# UPD70F3508 register map
Vendor: Renesas; Series: V850E2/Px4; File version: 1.0
CPU: other r0p0, little endian, no MPU, FPU, 4 interrupt priority bits
Registers are 8-bit, read-write, reset 0x0 unless marked. A register's access mark holds for its fields unless they carry their own. Offsets are from the block's base; [hi:lo] are bit positions; {n}, {i} and the like mark numbered series.

## INTC — Interrupt Controller
Base 0xFFFF6000
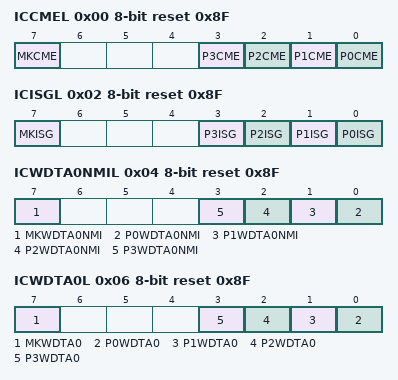
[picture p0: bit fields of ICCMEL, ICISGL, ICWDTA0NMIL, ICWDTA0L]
0x00 ICCMEL reset 0x8F — EI Level Interrupt Control Reg (low byte) ICCME
  [7] MKCME — Interrupt mask bit
  [n] P{n}CME (n=0..3) — Priority bit {n}
0x01 ICCMEH — EI Level Interrupt Control Reg (high byte) ICCME
  [4] RFCME — Interrupt request flag
0x02 ICISGL reset 0x8F — EI Level Interrupt Control Reg (low byte) ICISG
  [7] MKISG — Interrupt mask bit
  [n] P{n}ISG (n=0..3) — Priority bit {n}
0x03 ICISGH — EI Level Interrupt Control Reg (high byte) ICISG
  [4] RFISG — Interrupt request flag
0x04 ICWDTA0NMIL reset 0x8F — EI Level Interrupt Control Reg (low byte) ICWDTA0NMI
  [7] MKWDTA0NMI — Interrupt mask bit
  [n] P{n}WDTA0NMI (n=0..3) — Priority bit {n}
0x05 ICWDTA0NMIH — EI Level Interrupt Control Reg (high byte) ICWDTA0NMI
  [4] RFWDTA0NMI — Interrupt request flag
0x06 ICWDTA0L reset 0x8F — EI Level Interrupt Control Reg (low byte) ICWDTA0
  [7] MKWDTA0 — Interrupt mask bit
  [n] P{n}WDTA0 (n=0..3) — Priority bit {n}
0x07 ICWDTA0H — EI Level Interrupt Control Reg (high byte) ICWDTA0
  [4] RFWDTA0 — Interrupt request flag
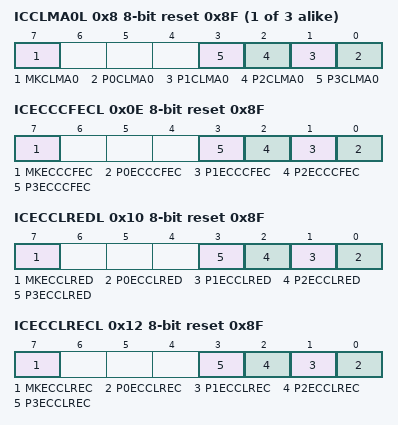
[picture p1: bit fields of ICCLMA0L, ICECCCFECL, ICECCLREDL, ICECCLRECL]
{0x8+2i} ICCLMA{i}L reset 0x8F (i=0..2) — EI Level Interrupt Control Reg (low byte) ICCLMA{i}
  [7] MKCLMA{i} — Interrupt mask bit
  [n] P{n}CLMA{i} (n=0..3) — Priority bit {n}
{0x9+2i} ICCLMA{i}H (i=0..2) — EI Level Interrupt Control Reg (high byte) ICCLMA{i}
  [4] RFCLMA{i} — Interrupt request flag
0x0E ICECCCFECL reset 0x8F — EI Level Interrupt Control Reg (low byte) ICECCCFEC
  [7] MKECCCFEC — Interrupt mask bit
  [n] P{n}ECCCFEC (n=0..3) — Priority bit {n}
0x0F ICECCCFECH — EI Level Interrupt Control Reg (high byte) ICECCCFEC
  [4] RFECCCFEC — Interrupt request flag
0x10 ICECCLREDL reset 0x8F — EI Level Interrupt Control Reg (low byte) ICECCLRED
  [7] MKECCLRED — Interrupt mask bit
  [n] P{n}ECCLRED (n=0..3) — Priority bit {n}
0x11 ICECCLREDH — EI Level Interrupt Control Reg (high byte) ICECCLRED
  [4] RFECCLRED — Interrupt request flag
0x12 ICECCLRECL reset 0x8F — EI Level Interrupt Control Reg (low byte) ICECCLREC
  [7] MKECCLREC — Interrupt mask bit
  [n] P{n}ECCLREC (n=0..3) — Priority bit {n}
0x13 ICECCLRECH — EI Level Interrupt Control Reg (high byte) ICECCLREC
  [4] RFECCLREC — Interrupt request flag
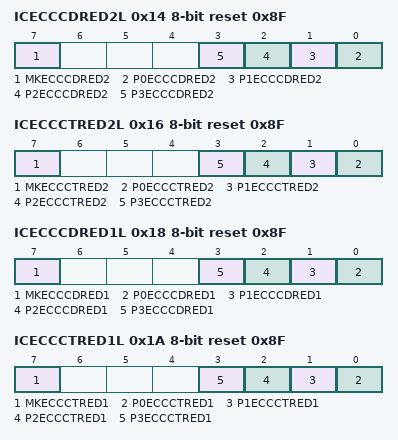
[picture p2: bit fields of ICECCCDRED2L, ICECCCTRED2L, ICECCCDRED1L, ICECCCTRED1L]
0x14 ICECCCDRED2L reset 0x8F — EI Level Interrupt Control Reg (low byte) ICECCCDRED2
  [7] MKECCCDRED2 — Interrupt mask bit
  [n] P{n}ECCCDRED2 (n=0..3) — Priority bit {n}
0x15 ICECCCDRED2H — EI Level Interrupt Control Reg (high byte) ICECCCDRED2
  [4] RFECCCDRED2 — Interrupt request flag
0x16 ICECCCTRED2L reset 0x8F — EI Level Interrupt Control Reg (low byte) ICECCCTRED2
  [7] MKECCCTRED2 — Interrupt mask bit
  [n] P{n}ECCCTRED2 (n=0..3) — Priority bit {n}
0x17 ICECCCTRED2H — EI Level Interrupt Control Reg (high byte) ICECCCTRED2
  [4] RFECCCTRED2 — Interrupt request flag
0x18 ICECCCDRED1L reset 0x8F — EI Level Interrupt Control Reg (low byte) ICECCCDRED1
  [7] MKECCCDRED1 — Interrupt mask bit
  [n] P{n}ECCCDRED1 (n=0..3) — Priority bit {n}
0x19 ICECCCDRED1H — EI Level Interrupt Control Reg (high byte) ICECCCDRED1
  [4] RFECCCDRED1 — Interrupt request flag
0x1A ICECCCTRED1L reset 0x8F — EI Level Interrupt Control Reg (low byte) ICECCCTRED1
  [7] MKECCCTRED1 — Interrupt mask bit
  [n] P{n}ECCCTRED1 (n=0..3) — Priority bit {n}
0x1B ICECCCTRED1H — EI Level Interrupt Control Reg (high byte) ICECCCTRED1
  [4] RFECCCTRED1 — Interrupt request flag
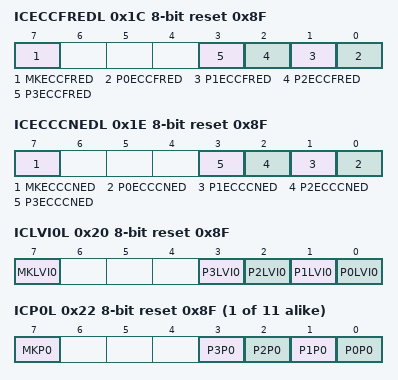
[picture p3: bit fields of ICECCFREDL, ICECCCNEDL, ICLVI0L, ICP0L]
0x1C ICECCFREDL reset 0x8F — EI Level Interrupt Control Reg (low byte) ICECCFRED
  [7] MKECCFRED — Interrupt mask bit
  [n] P{n}ECCFRED (n=0..3) — Priority bit {n}
0x1D ICECCFREDH — EI Level Interrupt Control Reg (high byte) ICECCFRED
  [4] RFECCFRED — Interrupt request flag
0x1E ICECCCNEDL reset 0x8F — EI Level Interrupt Control Reg (low byte) ICECCCNED
  [7] MKECCCNED — Interrupt mask bit
  [n] P{n}ECCCNED (n=0..3) — Priority bit {n}
0x1F ICECCCNEDH — EI Level Interrupt Control Reg (high byte) ICECCCNED
  [4] RFECCCNED — Interrupt request flag
0x20 ICLVI0L reset 0x8F — EI Level Interrupt Control Reg (low byte) ICLVI0
  [7] MKLVI0 — Interrupt mask bit
  [n] P{n}LVI0 (n=0..3) — Priority bit {n}
0x21 ICLVI0H — EI Level Interrupt Control Reg (high byte) ICLVI0
  [4] RFLVI0 — Interrupt request flag
{0x22+2i} ICP{i}L reset 0x8F (i=0..10) — EI Level Interrupt Control Reg (low byte) ICP{i}
  [7] MKP{i} — Interrupt mask bit
  [n] P{n}P{i} (n=0..3) — Priority bit {n}
{0x23+2i} ICP{i}H (i=0..10) — EI Level Interrupt Control Reg (high byte) ICP{i}
  [4] RFP{i} — Interrupt request flag
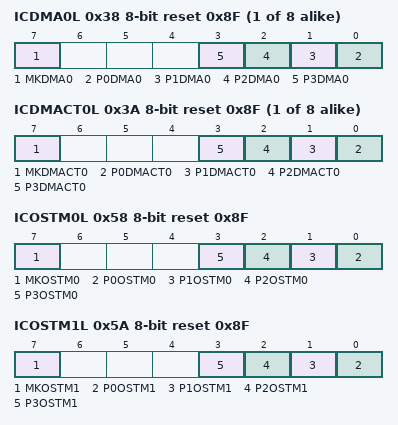
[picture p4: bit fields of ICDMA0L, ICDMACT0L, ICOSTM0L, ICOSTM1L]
{0x38+4i} ICDMA{i}L reset 0x8F (i=0..7) — EI Level Interrupt Control Reg (low byte) ICDMA{i}
  [7] MKDMA{i} — Interrupt mask bit
  [n] P{n}DMA{i} (n=0..3) — Priority bit {n}
{0x39+4i} ICDMA{i}H (i=0..7) — EI Level Interrupt Control Reg (high byte) ICDMA{i}
  [4] RFDMA{i} — Interrupt request flag
{0x3A+4i} ICDMACT{i}L reset 0x8F (i=0..7) — EI Level Interrupt Control Reg (low byte) ICDMACT{i}
  [7] MKDMACT{i} — Interrupt mask bit
  [n] P{n}DMACT{i} (n=0..3) — Priority bit {n}
{0x3B+4i} ICDMACT{i}H (i=0..7) — EI Level Interrupt Control Reg (high byte) ICDMACT{i}
  [4] RFDMACT{i} — Interrupt request flag
0x58 ICOSTM0L reset 0x8F — EI Level Interrupt Control Reg (low byte) ICOSTM0
  [7] MKOSTM0 — Interrupt mask bit
  [n] P{n}OSTM0 (n=0..3) — Priority bit {n}
0x59 ICOSTM0H — EI Level Interrupt Control Reg (high byte) ICOSTM0
  [4] RFOSTM0 — Interrupt request flag
0x5A ICOSTM1L reset 0x8F — EI Level Interrupt Control Reg (low byte) ICOSTM1
  [7] MKOSTM1 — Interrupt mask bit
  [n] P{n}OSTM1 (n=0..3) — Priority bit {n}
0x5B ICOSTM1H — EI Level Interrupt Control Reg (high byte) ICOSTM1
  [4] RFOSTM1 — Interrupt request flag
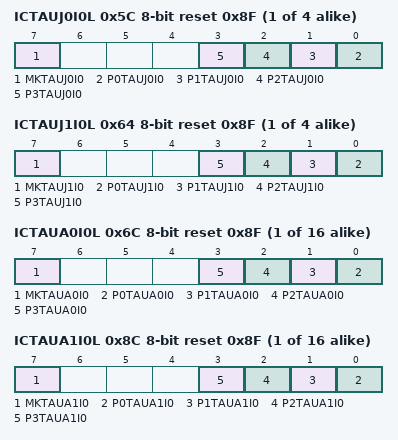
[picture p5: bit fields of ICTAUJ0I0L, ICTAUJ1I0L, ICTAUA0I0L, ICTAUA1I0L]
{0x5C+2i} ICTAUJ0I{i}L reset 0x8F (i=0..3) — EI Level Interrupt Control Reg (low byte) ICTAUJ0I{i}
  [7] MKTAUJ0I{i} — Interrupt mask bit
  [n] P{n}TAUJ0I{i} (n=0..3) — Priority bit {n}
{0x5D+2i} ICTAUJ0I{i}H (i=0..3) — EI Level Interrupt Control Reg (high byte) ICTAUJ0I{i}
  [4] RFTAUJ0I{i} — Interrupt request flag
{0x64+2i} ICTAUJ1I{i}L reset 0x8F (i=0..3) — EI Level Interrupt Control Reg (low byte) ICTAUJ1I{i}
  [7] MKTAUJ1I{i} — Interrupt mask bit
  [n] P{n}TAUJ1I{i} (n=0..3) — Priority bit {n}
{0x65+2i} ICTAUJ1I{i}H (i=0..3) — EI Level Interrupt Control Reg (high byte) ICTAUJ1I{i}
  [4] RFTAUJ1I{i} — Interrupt request flag
{0x6C+2i} ICTAUA0I{i}L reset 0x8F (i=0..15) — EI Level Interrupt Control Reg (low byte) ICTAUA0I{i}
  [7] MKTAUA0I{i} — Interrupt mask bit
  [n] P{n}TAUA0I{i} (n=0..3) — Priority bit {n}
{0x6D+2i} ICTAUA0I{i}H (i=0..15) — EI Level Interrupt Control Reg (high byte) ICTAUA0I{i}
  [4] RFTAUA0I{i} — Interrupt request flag
{0x8C+2i} ICTAUA1I{i}L reset 0x8F (i=0..15) — EI Level Interrupt Control Reg (low byte) ICTAUA1I{i}
  [7] MKTAUA1I{i} — Interrupt mask bit
  [n] P{n}TAUA1I{i} (n=0..3) — Priority bit {n}
{0x8D+2i} ICTAUA1I{i}H (i=0..15) — EI Level Interrupt Control Reg (high byte) ICTAUA1I{i}
  [4] RFTAUA1I{i} — Interrupt request flag
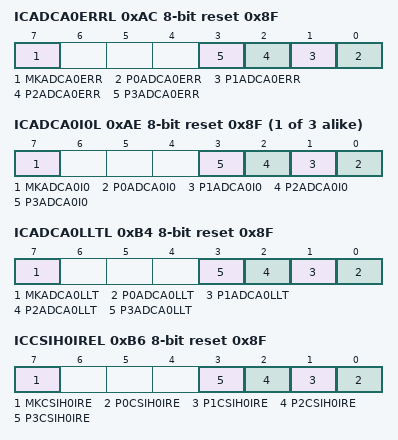
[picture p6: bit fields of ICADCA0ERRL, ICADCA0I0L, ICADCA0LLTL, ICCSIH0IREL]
0xAC ICADCA0ERRL reset 0x8F — EI Level Interrupt Control Reg (low byte) ICADCA0ERR
  [7] MKADCA0ERR — Interrupt mask bit
  [n] P{n}ADCA0ERR (n=0..3) — Priority bit {n}
0xAD ICADCA0ERRH — EI Level Interrupt Control Reg (high byte) ICADCA0ERR
  [4] RFADCA0ERR — Interrupt request flag
{0xAE+2i} ICADCA0I{i}L reset 0x8F (i=0..2) — EI Level Interrupt Control Reg (low byte) ICADCA0I{i}
  [7] MKADCA0I{i} — Interrupt mask bit
  [n] P{n}ADCA0I{i} (n=0..3) — Priority bit {n}
{0xAF+2i} ICADCA0I{i}H (i=0..2) — EI Level Interrupt Control Reg (high byte) ICADCA0I{i}
  [4] RFADCA0I{i} — Interrupt request flag
0xB4 ICADCA0LLTL reset 0x8F — EI Level Interrupt Control Reg (low byte) ICADCA0LLT
  [7] MKADCA0LLT — Interrupt mask bit
  [n] P{n}ADCA0LLT (n=0..3) — Priority bit {n}
0xB5 ICADCA0LLTH — EI Level Interrupt Control Reg (high byte) ICADCA0LLT
  [4] RFADCA0LLT — Interrupt request flag
0xB6 ICCSIH0IREL reset 0x8F — EI Level Interrupt Control Reg (low byte) ICCSIH0IRE
  [7] MKCSIH0IRE — Interrupt mask bit
  [n] P{n}CSIH0IRE (n=0..3) — Priority bit {n}
0xB7 ICCSIH0IREH — EI Level Interrupt Control Reg (high byte) ICCSIH0IRE
  [4] RFCSIH0IRE — Interrupt request flag
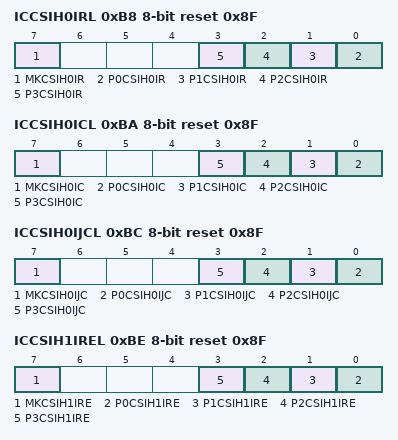
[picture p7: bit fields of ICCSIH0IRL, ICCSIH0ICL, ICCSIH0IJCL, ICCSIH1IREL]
0xB8 ICCSIH0IRL reset 0x8F — EI Level Interrupt Control Reg (low byte) ICCSIH0IR
  [7] MKCSIH0IR — Interrupt mask bit
  [n] P{n}CSIH0IR (n=0..3) — Priority bit {n}
0xB9 ICCSIH0IRH — EI Level Interrupt Control Reg (high byte) ICCSIH0IR
  [4] RFCSIH0IR — Interrupt request flag
0xBA ICCSIH0ICL reset 0x8F — EI Level Interrupt Control Reg (low byte) ICCSIH0IC
  [7] MKCSIH0IC — Interrupt mask bit
  [n] P{n}CSIH0IC (n=0..3) — Priority bit {n}
0xBB ICCSIH0ICH — EI Level Interrupt Control Reg (high byte) ICCSIH0IC
  [4] RFCSIH0IC — Interrupt request flag
0xBC ICCSIH0IJCL reset 0x8F — EI Level Interrupt Control Reg (low byte) ICCSIH0IJC
  [7] MKCSIH0IJC — Interrupt mask bit
  [n] P{n}CSIH0IJC (n=0..3) — Priority bit {n}
0xBD ICCSIH0IJCH — EI Level Interrupt Control Reg (high byte) ICCSIH0IJC
  [4] RFCSIH0IJC — Interrupt request flag
0xBE ICCSIH1IREL reset 0x8F — EI Level Interrupt Control Reg (low byte) ICCSIH1IRE
  [7] MKCSIH1IRE — Interrupt mask bit
  [n] P{n}CSIH1IRE (n=0..3) — Priority bit {n}
0xBF ICCSIH1IREH — EI Level Interrupt Control Reg (high byte) ICCSIH1IRE
  [4] RFCSIH1IRE — Interrupt request flag
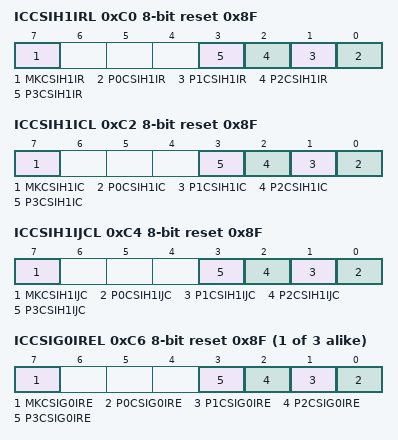
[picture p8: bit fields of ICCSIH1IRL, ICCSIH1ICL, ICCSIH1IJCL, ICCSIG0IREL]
0xC0 ICCSIH1IRL reset 0x8F — EI Level Interrupt Control Reg (low byte) ICCSIH1IR
  [7] MKCSIH1IR — Interrupt mask bit
  [n] P{n}CSIH1IR (n=0..3) — Priority bit {n}
0xC1 ICCSIH1IRH — EI Level Interrupt Control Reg (high byte) ICCSIH1IR
  [4] RFCSIH1IR — Interrupt request flag
0xC2 ICCSIH1ICL reset 0x8F — EI Level Interrupt Control Reg (low byte) ICCSIH1IC
  [7] MKCSIH1IC — Interrupt mask bit
  [n] P{n}CSIH1IC (n=0..3) — Priority bit {n}
0xC3 ICCSIH1ICH — EI Level Interrupt Control Reg (high byte) ICCSIH1IC
  [4] RFCSIH1IC — Interrupt request flag
0xC4 ICCSIH1IJCL reset 0x8F — EI Level Interrupt Control Reg (low byte) ICCSIH1IJC
  [7] MKCSIH1IJC — Interrupt mask bit
  [n] P{n}CSIH1IJC (n=0..3) — Priority bit {n}
0xC5 ICCSIH1IJCH — EI Level Interrupt Control Reg (high byte) ICCSIH1IJC
  [4] RFCSIH1IJC — Interrupt request flag
{0xC6+6i} ICCSIG{i}IREL reset 0x8F (i=0..2) — EI Level Interrupt Control Reg (low byte) ICCSIG{i}IRE
  [7] MKCSIG{i}IRE — Interrupt mask bit
  [n] P{n}CSIG{i}IRE (n=0..3) — Priority bit {n}
{0xC7+6i} ICCSIG{i}IREH (i=0..2) — EI Level Interrupt Control Reg (high byte) ICCSIG{i}IRE
  [4] RFCSIG{i}IRE — Interrupt request flag
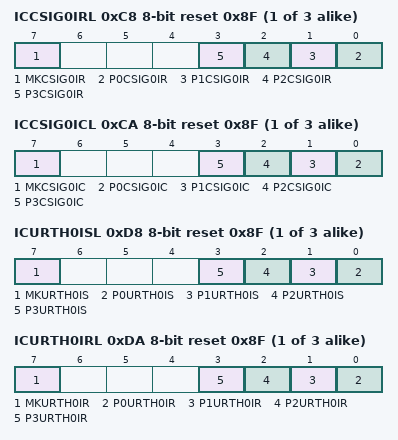
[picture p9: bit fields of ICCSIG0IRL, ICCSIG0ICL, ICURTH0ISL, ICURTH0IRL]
{0xC8+6i} ICCSIG{i}IRL reset 0x8F (i=0..2) — EI Level Interrupt Control Reg (low byte) ICCSIG{i}IR
  [7] MKCSIG{i}IR — Interrupt mask bit
  [n] P{n}CSIG{i}IR (n=0..3) — Priority bit {n}
{0xC9+6i} ICCSIG{i}IRH (i=0..2) — EI Level Interrupt Control Reg (high byte) ICCSIG{i}IR
  [4] RFCSIG{i}IR — Interrupt request flag
{0xCA+6i} ICCSIG{i}ICL reset 0x8F (i=0..2) — EI Level Interrupt Control Reg (low byte) ICCSIG{i}IC
  [7] MKCSIG{i}IC — Interrupt mask bit
  [n] P{n}CSIG{i}IC (n=0..3) — Priority bit {n}
{0xCB+6i} ICCSIG{i}ICH (i=0..2) — EI Level Interrupt Control Reg (high byte) ICCSIG{i}IC
  [4] RFCSIG{i}IC — Interrupt request flag
{0xD8+6i} ICURTH{i}ISL reset 0x8F (i=0..2) — EI Level Interrupt Control Reg (low byte) ICURTH{i}IS
  [7] MKURTH{i}IS — Interrupt mask bit
  [n] P{n}URTH{i}IS (n=0..3) — Priority bit {n}
{0xD9+6i} ICURTH{i}ISH (i=0..2) — EI Level Interrupt Control Reg (high byte) ICURTH{i}IS
  [4] RFURTH{i}IS — Interrupt request flag
{0xDA+6i} ICURTH{i}IRL reset 0x8F (i=0..2) — EI Level Interrupt Control Reg (low byte) ICURTH{i}IR
  [7] MKURTH{i}IR — Interrupt mask bit
  [n] P{n}URTH{i}IR (n=0..3) — Priority bit {n}
{0xDB+6i} ICURTH{i}IRH (i=0..2) — EI Level Interrupt Control Reg (high byte) ICURTH{i}IR
  [4] RFURTH{i}IR — Interrupt request flag
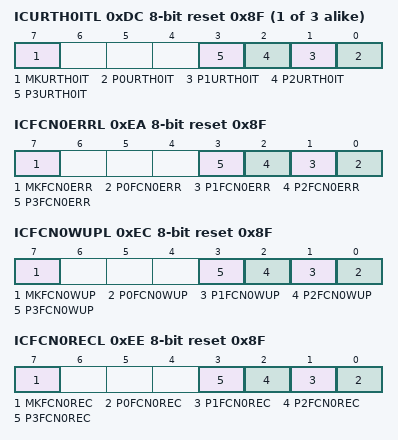
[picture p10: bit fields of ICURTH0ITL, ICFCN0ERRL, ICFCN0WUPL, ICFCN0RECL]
{0xDC+6i} ICURTH{i}ITL reset 0x8F (i=0..2) — EI Level Interrupt Control Reg (low byte) ICURTH{i}IT
  [7] MKURTH{i}IT — Interrupt mask bit
  [n] P{n}URTH{i}IT (n=0..3) — Priority bit {n}
{0xDD+6i} ICURTH{i}ITH (i=0..2) — EI Level Interrupt Control Reg (high byte) ICURTH{i}IT
  [4] RFURTH{i}IT — Interrupt request flag
0xEA ICFCN0ERRL reset 0x8F — EI Level Interrupt Control Reg (low byte) ICFCN0ERR
  [7] MKFCN0ERR — Interrupt mask bit
  [n] P{n}FCN0ERR (n=0..3) — Priority bit {n}
0xEB ICFCN0ERRH — EI Level Interrupt Control Reg (high byte) ICFCN0ERR
  [4] RFFCN0ERR — Interrupt request flag
0xEC ICFCN0WUPL reset 0x8F — EI Level Interrupt Control Reg (low byte) ICFCN0WUP
  [7] MKFCN0WUP — Interrupt mask bit
  [n] P{n}FCN0WUP (n=0..3) — Priority bit {n}
0xED ICFCN0WUPH — EI Level Interrupt Control Reg (high byte) ICFCN0WUP
  [4] RFFCN0WUP — Interrupt request flag
0xEE ICFCN0RECL reset 0x8F — EI Level Interrupt Control Reg (low byte) ICFCN0REC
  [7] MKFCN0REC — Interrupt mask bit
  [n] P{n}FCN0REC (n=0..3) — Priority bit {n}
0xEF ICFCN0RECH — EI Level Interrupt Control Reg (high byte) ICFCN0REC
  [4] RFFCN0REC — Interrupt request flag
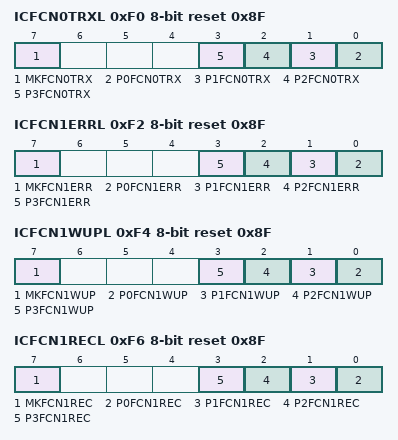
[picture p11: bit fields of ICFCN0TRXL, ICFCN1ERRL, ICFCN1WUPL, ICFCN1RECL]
0xF0 ICFCN0TRXL reset 0x8F — EI Level Interrupt Control Reg (low byte) ICFCN0TRX
  [7] MKFCN0TRX — Interrupt mask bit
  [n] P{n}FCN0TRX (n=0..3) — Priority bit {n}
0xF1 ICFCN0TRXH — EI Level Interrupt Control Reg (high byte) ICFCN0TRX
  [4] RFFCN0TRX — Interrupt request flag
0xF2 ICFCN1ERRL reset 0x8F — EI Level Interrupt Control Reg (low byte) ICFCN1ERR
  [7] MKFCN1ERR — Interrupt mask bit
  [n] P{n}FCN1ERR (n=0..3) — Priority bit {n}
0xF3 ICFCN1ERRH — EI Level Interrupt Control Reg (high byte) ICFCN1ERR
  [4] RFFCN1ERR — Interrupt request flag
0xF4 ICFCN1WUPL reset 0x8F — EI Level Interrupt Control Reg (low byte) ICFCN1WUP
  [7] MKFCN1WUP — Interrupt mask bit
  [n] P{n}FCN1WUP (n=0..3) — Priority bit {n}
0xF5 ICFCN1WUPH — EI Level Interrupt Control Reg (high byte) ICFCN1WUP
  [4] RFFCN1WUP — Interrupt request flag
0xF6 ICFCN1RECL reset 0x8F — EI Level Interrupt Control Reg (low byte) ICFCN1REC
  [7] MKFCN1REC — Interrupt mask bit
  [n] P{n}FCN1REC (n=0..3) — Priority bit {n}
0xF7 ICFCN1RECH — EI Level Interrupt Control Reg (high byte) ICFCN1REC
  [4] RFFCN1REC — Interrupt request flag
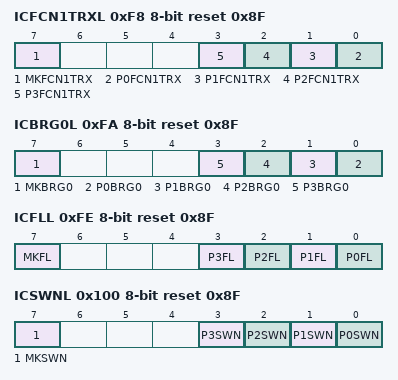
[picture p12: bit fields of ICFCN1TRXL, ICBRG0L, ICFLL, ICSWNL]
0xF8 ICFCN1TRXL reset 0x8F — EI Level Interrupt Control Reg (low byte) ICFCN1TRX
  [7] MKFCN1TRX — Interrupt mask bit
  [n] P{n}FCN1TRX (n=0..3) — Priority bit {n}
0xF9 ICFCN1TRXH — EI Level Interrupt Control Reg (high byte) ICFCN1TRX
  [4] RFFCN1TRX — Interrupt request flag
0xFA ICBRG0L reset 0x8F — EI Level Interrupt Control Reg (low byte) ICBRG0
  [7] MKBRG0 — Interrupt mask bit
  [n] P{n}BRG0 (n=0..3) — Priority bit {n}
0xFB ICBRG0H — EI Level Interrupt Control Reg (high byte) ICBRG0
  [4] RFBRG0 — Interrupt request flag
0xFE ICFLL reset 0x8F — EI Level Interrupt Control Reg (low byte) ICFL
  [7] MKFL — Interrupt mask bit
  [n] P{n}FL (n=0..3) — Priority bit {n}
0xFF ICFLH — EI Level Interrupt Control Reg (high byte) ICFL
  [4] RFFL — Interrupt request flag
0x100 ICSWNL reset 0x8F — EI Level Interrupt Control Reg (low byte) ICSWN
  [7] MKSWN — Interrupt mask bit
  [n] P{n}SWN (n=0..3) — Priority bit {n}
0x101 ICSWNH — EI Level Interrupt Control Reg (high byte) ICSWN
  [4] RFSWN — Interrupt request flag
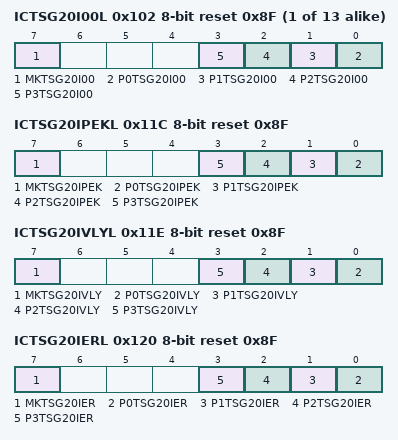
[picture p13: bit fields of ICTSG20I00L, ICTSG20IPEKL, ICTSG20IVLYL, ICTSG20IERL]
{0x102+2i} ICTSG20I{i:02}L reset 0x8F (i=0..12) — EI Level Interrupt Control Reg (low byte) ICTSG20I{i:02}
  [7] MKTSG20I{i:02} — Interrupt mask bit
  [n] P{n}TSG20I{i:02} (n=0..3) — Priority bit {n}
{0x103+2i} ICTSG20I{i:02}H (i=0..12) — EI Level Interrupt Control Reg (high byte) ICTSG20I{i:02}
  [4] RFTSG20I{i:02} — Interrupt request flag
0x11C ICTSG20IPEKL reset 0x8F — EI Level Interrupt Control Reg (low byte) ICTSG20IPEK
  [7] MKTSG20IPEK — Interrupt mask bit
  [n] P{n}TSG20IPEK (n=0..3) — Priority bit {n}
0x11D ICTSG20IPEKH — EI Level Interrupt Control Reg (high byte) ICTSG20IPEK
  [4] RFTSG20IPEK — Interrupt request flag
0x11E ICTSG20IVLYL reset 0x8F — EI Level Interrupt Control Reg (low byte) ICTSG20IVLY
  [7] MKTSG20IVLY — Interrupt mask bit
  [n] P{n}TSG20IVLY (n=0..3) — Priority bit {n}
0x11F ICTSG20IVLYH — EI Level Interrupt Control Reg (high byte) ICTSG20IVLY
  [4] RFTSG20IVLY — Interrupt request flag
0x120 ICTSG20IERL reset 0x8F — EI Level Interrupt Control Reg (low byte) ICTSG20IER
  [7] MKTSG20IER — Interrupt mask bit
  [n] P{n}TSG20IER (n=0..3) — Priority bit {n}
0x121 ICTSG20IERH — EI Level Interrupt Control Reg (high byte) ICTSG20IER
  [4] RFTSG20IER — Interrupt request flag
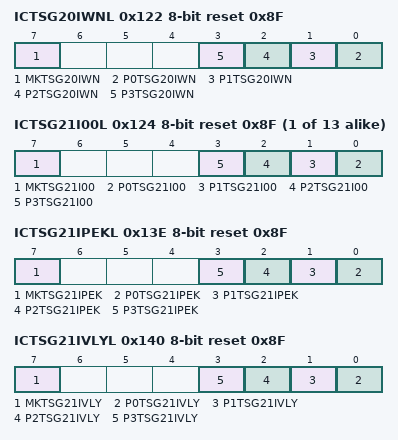
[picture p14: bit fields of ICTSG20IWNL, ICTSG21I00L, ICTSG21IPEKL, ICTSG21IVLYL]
0x122 ICTSG20IWNL reset 0x8F — EI Level Interrupt Control Reg (low byte) ICTSG20IWN
  [7] MKTSG20IWN — Interrupt mask bit
  [n] P{n}TSG20IWN (n=0..3) — Priority bit {n}
0x123 ICTSG20IWNH — EI Level Interrupt Control Reg (high byte) ICTSG20IWN
  [4] RFTSG20IWN — Interrupt request flag
{0x124+2i} ICTSG21I{i:02}L reset 0x8F (i=0..12) — EI Level Interrupt Control Reg (low byte) ICTSG21I{i:02}
  [7] MKTSG21I{i:02} — Interrupt mask bit
  [n] P{n}TSG21I{i:02} (n=0..3) — Priority bit {n}
{0x125+2i} ICTSG21I{i:02}H (i=0..12) — EI Level Interrupt Control Reg (high byte) ICTSG21I{i:02}
  [4] RFTSG21I{i:02} — Interrupt request flag
0x13E ICTSG21IPEKL reset 0x8F — EI Level Interrupt Control Reg (low byte) ICTSG21IPEK
  [7] MKTSG21IPEK — Interrupt mask bit
  [n] P{n}TSG21IPEK (n=0..3) — Priority bit {n}
0x13F ICTSG21IPEKH — EI Level Interrupt Control Reg (high byte) ICTSG21IPEK
  [4] RFTSG21IPEK — Interrupt request flag
0x140 ICTSG21IVLYL reset 0x8F — EI Level Interrupt Control Reg (low byte) ICTSG21IVLY
  [7] MKTSG21IVLY — Interrupt mask bit
  [n] P{n}TSG21IVLY (n=0..3) — Priority bit {n}
0x141 ICTSG21IVLYH — EI Level Interrupt Control Reg (high byte) ICTSG21IVLY
  [4] RFTSG21IVLY — Interrupt request flag
0x142 ICTSG21IERL reset 0x8F — EI Level Interrupt Control Reg (low byte) ICTSG21IER
  [7] MKTSG21IER — Interrupt mask bit
  [n] P{n}TSG21IER (n=0..3) — Priority bit {n}
0x143 ICTSG21IERH — EI Level Interrupt Control Reg (high byte) ICTSG21IER
  [4] RFTSG21IER — Interrupt request flag
0x144 ICTSG21IWNL reset 0x8F — EI Level Interrupt Control Reg (low byte) ICTSG21IWN
  [7] MKTSG21IWN — Interrupt mask bit
  [n] P{n}TSG21IWN (n=0..3) — Priority bit {n}
0x145 ICTSG21IWNH — EI Level Interrupt Control Reg (high byte) ICTSG21IWN
  [4] RFTSG21IWN — Interrupt request flag
0x146 ICENCA0IOVL reset 0x8F — EI Level Interrupt Control Reg (low byte) ICENCA0IOV
  [7] MKENCA0IOV — Interrupt mask bit
  [n] P{n}ENCA0IOV (n=0..3) — Priority bit {n}
0x147 ICENCA0IOVH — EI Level Interrupt Control Reg (high byte) ICENCA0IOV
  [4] RFENCA0IOV — Interrupt request flag
0x148 ICENCA0I0L reset 0x8F — EI Level Interrupt Control Reg (low byte) ICENCA0I0
  [7] MKENCA0I0 — Interrupt mask bit
  [n] P{n}ENCA0I0 (n=0..3) — Priority bit {n}
0x149 ICENCA0I0H — EI Level Interrupt Control Reg (high byte) ICENCA0I0
  [4] RFENCA0I0 — Interrupt request flag
0x14A ICENCA0I1L reset 0x8F — EI Level Interrupt Control Reg (low byte) ICENCA0I1
  [7] MKENCA0I1 — Interrupt mask bit
  [n] P{n}ENCA0I1 (n=0..3) — Priority bit {n}
0x14B ICENCA0I1H — EI Level Interrupt Control Reg (high byte) ICENCA0I1
  [4] RFENCA0I1 — Interrupt request flag
0x14C ICENCA0IUDL reset 0x8F — EI Level Interrupt Control Reg (low byte) ICENCA0IUD
  [7] MKENCA0IUD — Interrupt mask bit
  [n] P{n}ENCA0IUD (n=0..3) — Priority bit {n}
0x14D ICENCA0IUDH — EI Level Interrupt Control Reg (high byte) ICENCA0IUD
  [4] RFENCA0IUD — Interrupt request flag
0x14E ICENCA0IECL reset 0x8F — EI Level Interrupt Control Reg (low byte) ICENCA0IEC
  [7] MKENCA0IEC — Interrupt mask bit
  [n] P{n}ENCA0IEC (n=0..3) — Priority bit {n}
0x14F ICENCA0IECH — EI Level Interrupt Control Reg (high byte) ICENCA0IEC
  [4] RFENCA0IEC — Interrupt request flag
0x150 ICENCA1IOVL reset 0x8F — EI Level Interrupt Control Reg (low byte) ICENCA1IOV
  [7] MKENCA1IOV — Interrupt mask bit
  [n] P{n}ENCA1IOV (n=0..3) — Priority bit {n}
0x151 ICENCA1IOVH — EI Level Interrupt Control Reg (high byte) ICENCA1IOV
  [4] RFENCA1IOV — Interrupt request flag
0x152 ICENCA1I0L reset 0x8F — EI Level Interrupt Control Reg (low byte) ICENCA1I0
  [7] MKENCA1I0 — Interrupt mask bit
  [n] P{n}ENCA1I0 (n=0..3) — Priority bit {n}
0x153 ICENCA1I0H — EI Level Interrupt Control Reg (high byte) ICENCA1I0
  [4] RFENCA1I0 — Interrupt request flag
0x154 ICENCA1I1L reset 0x8F — EI Level Interrupt Control Reg (low byte) ICENCA1I1
  [7] MKENCA1I1 — Interrupt mask bit
  [n] P{n}ENCA1I1 (n=0..3) — Priority bit {n}
0x155 ICENCA1I1H — EI Level Interrupt Control Reg (high byte) ICENCA1I1
  [4] RFENCA1I1 — Interrupt request flag
0x156 ICENCA1IUDL reset 0x8F — EI Level Interrupt Control Reg (low byte) ICENCA1IUD
  [7] MKENCA1IUD — Interrupt mask bit
  [n] P{n}ENCA1IUD (n=0..3) — Priority bit {n}
0x157 ICENCA1IUDH — EI Level Interrupt Control Reg (high byte) ICENCA1IUD
  [4] RFENCA1IUD — Interrupt request flag
0x158 ICENCA1IECL reset 0x8F — EI Level Interrupt Control Reg (low byte) ICENCA1IEC
  [7] MKENCA1IEC — Interrupt mask bit
  [n] P{n}ENCA1IEC (n=0..3) — Priority bit {n}
0x159 ICENCA1IECH — EI Level Interrupt Control Reg (high byte) ICENCA1IEC
  [4] RFENCA1IEC — Interrupt request flag
0x15A ICTPBA0IPRDL reset 0x8F — EI Level Interrupt Control Reg (low byte) ICTPBA0IPRD
  [7] MKTPBA0IPRD — Interrupt mask bit
  [n] P{n}TPBA0IPRD (n=0..3) — Priority bit {n}
0x15B ICTPBA0IPRDH — EI Level Interrupt Control Reg (high byte) ICTPBA0IPRD
  [4] RFTPBA0IPRD — Interrupt request flag
0x15C ICTPBA0IDTYL reset 0x8F — EI Level Interrupt Control Reg (low byte) ICTPBA0IDTY
  [7] MKTPBA0IDTY — Interrupt mask bit
  [n] P{n}TPBA0IDTY (n=0..3) — Priority bit {n}
0x15D ICTPBA0IDTYH — EI Level Interrupt Control Reg (high byte) ICTPBA0IDTY
  [4] RFTPBA0IDTY — Interrupt request flag
0x15E ICTPBA0IPATL reset 0x8F — EI Level Interrupt Control Reg (low byte) ICTPBA0IPAT
  [7] MKTPBA0IPAT — Interrupt mask bit
  [n] P{n}TPBA0IPAT (n=0..3) — Priority bit {n}
0x15F ICTPBA0IPATH — EI Level Interrupt Control Reg (high byte) ICTPBA0IPAT
  [4] RFTPBA0IPAT — Interrupt request flag
0x160 ICTPBA1IPRDL reset 0x8F — EI Level Interrupt Control Reg (low byte) ICTPBA1IPRD
  [7] MKTPBA1IPRD — Interrupt mask bit
  [n] P{n}TPBA1IPRD (n=0..3) — Priority bit {n}
0x161 ICTPBA1IPRDH — EI Level Interrupt Control Reg (high byte) ICTPBA1IPRD
  [4] RFTPBA1IPRD — Interrupt request flag
0x162 ICTPBA1IDTYL reset 0x8F — EI Level Interrupt Control Reg (low byte) ICTPBA1IDTY
  [7] MKTPBA1IDTY — Interrupt mask bit
  [n] P{n}TPBA1IDTY (n=0..3) — Priority bit {n}
0x163 ICTPBA1IDTYH — EI Level Interrupt Control Reg (high byte) ICTPBA1IDTY
  [4] RFTPBA1IDTY — Interrupt request flag
0x164 ICTPBA1IPATL reset 0x8F — EI Level Interrupt Control Reg (low byte) ICTPBA1IPAT
  [7] MKTPBA1IPAT — Interrupt mask bit
  [n] P{n}TPBA1IPAT (n=0..3) — Priority bit {n}
0x165 ICTPBA1IPATH — EI Level Interrupt Control Reg (high byte) ICTPBA1IPAT
  [4] RFTPBA1IPAT — Interrupt request flag
0x16A ICTAPA0IPEK0L reset 0x8F — EI Level Interrupt Control Reg (low byte) ICTAPA0IPEK0
  [7] MKTAPA0IPEK0 — Interrupt mask bit
  [n] P{n}TAPA0IPEK0 (n=0..3) — Priority bit {n}
0x16B ICTAPA0IPEK0H — EI Level Interrupt Control Reg (high byte) ICTAPA0IPEK0
  [4] RFTAPA0IPEK0 — Interrupt request flag
0x16C ICTAPA0IVLY0L reset 0x8F — EI Level Interrupt Control Reg (low byte) ICTAPA0IVLY0
  [7] MKTAPA0IVLY0 — Interrupt mask bit
  [n] P{n}TAPA0IVLY0 (n=0..3) — Priority bit {n}
0x16D ICTAPA0IVLY0H — EI Level Interrupt Control Reg (high byte) ICTAPA0IVLY0
  [4] RFTAPA0IVLY0 — Interrupt request flag
0x16E ICTAPA1IPEK0L reset 0x8F — EI Level Interrupt Control Reg (low byte) ICTAPA1IPEK0
  [7] MKTAPA1IPEK0 — Interrupt mask bit
  [n] P{n}TAPA1IPEK0 (n=0..3) — Priority bit {n}
0x16F ICTAPA1IPEK0H — EI Level Interrupt Control Reg (high byte) ICTAPA1IPEK0
  [4] RFTAPA1IPEK0 — Interrupt request flag
0x170 ICTAPA1IVLY0L reset 0x8F — EI Level Interrupt Control Reg (low byte) ICTAPA1IVLY0
  [7] MKTAPA1IVLY0 — Interrupt mask bit
  [n] P{n}TAPA1IVLY0 (n=0..3) — Priority bit {n}
0x171 ICTAPA1IVLY0H — EI Level Interrupt Control Reg (high byte) ICTAPA1IVLY0
  [4] RFTAPA1IVLY0 — Interrupt request flag
{0x172+2i} ICFLX0I{i}L reset 0x8F (i=0..3) — EI Level Interrupt Control Reg (low byte) ICFLX0I{i}
  [7] MKFLX0I{i} — Interrupt mask bit
  [n] P{n}FLX0I{i} (n=0..3) — Priority bit {n}
{0x173+2i} ICFLX0I{i}H (i=0..3) — EI Level Interrupt Control Reg (high byte) ICFLX0I{i}
  [4] RFFLX0I{i} — Interrupt request flag
0x17A ICFLX0SIFL08L reset 0x8F — EI Level Interrupt Control Reg (low byte) ICFLX0SIFL08
  [7] MKFLX0SIFL08 — Interrupt mask bit
  [n] P{n}FLX0SIFL08 (n=0..3) — Priority bit {n}
0x17B ICFLX0SIFL08H — EI Level Interrupt Control Reg (high byte) ICFLX0SIFL08
  [4] RFFLX0SIFL08 — Interrupt request flag
0x17C ICFLX0SIFL09L reset 0x8F — EI Level Interrupt Control Reg (low byte) ICFLX0SIFL09
  [7] MKFLX0SIFL09 — Interrupt mask bit
  [n] P{n}FLX0SIFL09 (n=0..3) — Priority bit {n}
0x17D ICFLX0SIFL09H — EI Level Interrupt Control Reg (high byte) ICFLX0SIFL09
  [4] RFFLX0SIFL09 — Interrupt request flag
0x17E ICFLX0SIFL02L reset 0x8F — EI Level Interrupt Control Reg (low byte) ICFLX0SIFL02
  [7] MKFLX0SIFL02 — Interrupt mask bit
  [n] P{n}FLX0SIFL02 (n=0..3) — Priority bit {n}
0x17F ICFLX0SIFL02H — EI Level Interrupt Control Reg (high byte) ICFLX0SIFL02
  [4] RFFLX0SIFL02 — Interrupt request flag
0x180 ICFLX0SIFL07L reset 0x8F — EI Level Interrupt Control Reg (low byte) ICFLX0SIFL07
  [7] MKFLX0SIFL07 — Interrupt mask bit
  [n] P{n}FLX0SIFL07 (n=0..3) — Priority bit {n}
0x181 ICFLX0SIFL07H — EI Level Interrupt Control Reg (high byte) ICFLX0SIFL07
  [4] RFFLX0SIFL07 — Interrupt request flag
{0x182+2i} ICSW{i}L reset 0x8F (i=0..9) — EI Level Interrupt Control Reg (low byte) ICSW{i}
  [7] MKSW{i} — Interrupt mask bit
  [n] P{n}SW{i} (n=0..3) — Priority bit {n}
{0x183+2i} ICSW{i}H (i=0..9) — EI Level Interrupt Control Reg (high byte) ICSW{i}
  [4] RFSW{i} — Interrupt request flag
0x400 IMR0 16-bit reset 0xFFFF — EI Level Interrupt Mask Register 0 (EIINT0 to EIINT15)
  [n] IMR0EIMK{n} (n=0..15) — Mask EIINT{n}
0x402 IMR1 16-bit reset 0xFFFF — EI Level Interrupt Mask Register 1 (EIINT16 to EIINT31)
  [n-16] IMR1EIMK{n} (n=16..31) — Mask EIINT{n}
0x404 IMR2 16-bit reset 0xFFFF — EI Level Interrupt Mask Register 2 (EIINT32 to EIINT47)
  [n-32] IMR2EIMK{n} (n=32..47) — Mask EIINT{n}
0x406 IMR3 16-bit reset 0xFFFF — EI Level Interrupt Mask Register 3 (EIINT48 to EIINT63)
  [n-48] IMR3EIMK{n} (n=48..63) — Mask EIINT{n}
0x408 IMR4 16-bit reset 0xFFFF — EI Level Interrupt Mask Register 4 (EIINT64 to EIINT79)
  [n-64] IMR4EIMK{n} (n=64..79) — Mask EIINT{n}
0x40A IMR5 16-bit reset 0xFFFF — EI Level Interrupt Mask Register 5 (EIINT80 to EIINT95)
  [n-80] IMR5EIMK{n} (n=80..95) — Mask EIINT{n}
0x40C IMR6 16-bit reset 0xFFFF — EI Level Interrupt Mask Register 6 (EIINT96 to EIINT111)
  [n-96] IMR6EIMK{n} (n=96..111) — Mask EIINT{n}
0x40E IMR7 16-bit reset 0xFFFF — EI Level Interrupt Mask Register 7 (EIINT112 to EIINT127)
  [n-112] IMR7EIMK{n} (n=112..127) — Mask EIINT{n}
0x410 IMR8 16-bit reset 0xFFFF — EI Level Interrupt Mask Register 8 (EIINT128 to EIINT143)
  [n-128] IMR8EIMK{n} (n=128..143) — Mask EIINT{n}
0x412 IMR9 16-bit reset 0xFFFF — EI Level Interrupt Mask Register 9 (EIINT144 to EIINT159)
  [n-144] IMR9EIMK{n} (n=144..159) — Mask EIINT{n}
0x414 IMR10 16-bit reset 0xFFFF — EI Level Interrupt Mask Register 10 (EIINT160 to EIINT175)
  [n-160] IMR10EIMK{n} (n=160..175) — Mask EIINT{n}
0x416 IMR11 16-bit reset 0xFFFF — EI Level Interrupt Mask Register 11 (EIINT176 to EIINT191)
  [n-176] IMR11EIMK{n} (n=176..191) — Mask EIINT{n}
0x418 IMR12 16-bit reset 0xFFFF — EI Level Interrupt Mask Register 12 (EIINT192 to EIINT202)
  [n-192] IMR12EIMK{n} (n=192..202) — Mask EIINT{n}
0x440 ISPR 16-bit ro — In-Service Priority Register
  [n] ISPR{n} (n=0..15) — Priority {n} in-service flag
0x448 PMR 16-bit — Priority Mask Register
  [n] PMR{n} (n=0..15) — Mask priority level {n}
0x450 ISPC 16-bit — In-Service Priority Clear Register
  [n] ISPC{n} (n=0..15) — ISPR clear control bit {n}
0x458 SCR 16-bit ro — Selected Channel Hold Register
  [n] SCR{n} (n=0..7) — Channel number bit {n}
0x45A ICSR 16-bit ro — Interrupt Controller Status Register
  [8] ICSRPMF — PMR-masked pending interrupt flag
  [6] ICSRFNR — FENMI issued to CPU
  [5] ICSRFIR — FEINT issued to CPU
  [4] ICSREIR — EIINT issued to CPU
  [2] ICSRFNE — CPU processing FENMI
  [1] ICSRFIE — CPU processing FEINT
  [0] ICSREIE — CPU processing EIINT
0x45C FNC 16-bit ro — FE Level NMI Status Register
  [12] FNRF — FENMI interrupt request flag
0x45E FIC 16-bit ro — FE Level INT Status Register
  [12] FIRF — FEINT interrupt request flag
